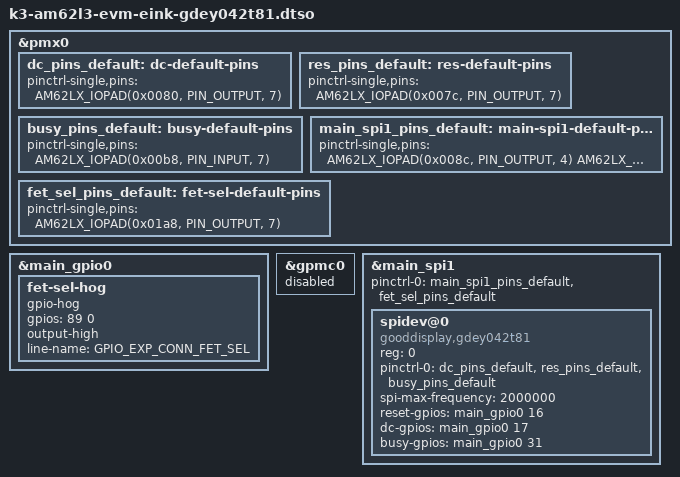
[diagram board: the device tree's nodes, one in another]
// SPDX-License-Identifier: GPL-2.0-or-later OR MIT
/**
 * DT Overlay for GoodDisplay GDEY042T81 E-Ink Display on AM62L3 EVM
 *
 * Pin mapping (matching k3-am62l3-evm-epaper.dtso):
 * P5  --> BUSY
 * P25 --> GND
 * P26 --> RST
 * P27 --> SPI CLK
 * P28 --> DC
 * P29 --> SPI DAT (MOSI)
 * P30 --> SPI CS
 *
 * Copyright (C) 2025 Texas Instruments Incorporated - https://www.ti.com/
 */

/dts-v1/;
/plugin/;

#include <dt-bindings/gpio/gpio.h>
#include "k3-pinctrl.h"

&pmx0 {
	dc_pins_default: dc-default-pins {
		pinctrl-single,pins = <
			AM62LX_IOPAD(0x0080, PIN_OUTPUT, 7) /* (K22) GPMC0_AD2.GPIO0_17 */
		>;
	};

	res_pins_default: res-default-pins {
		pinctrl-single,pins = <
			AM62LX_IOPAD(0x007c, PIN_OUTPUT, 7) /* (L23) GPMC0_AD1.GPIO0_16 */
		>;
	};

	busy_pins_default: busy-default-pins {
		pinctrl-single,pins = <
			AM62LX_IOPAD(0x00b8, PIN_INPUT, 7) /* (L21) GPMC0_AD0.GPIO0_31 */
		>;
	};

	main_spi1_pins_default: main-spi1-default-pins {
		pinctrl-single,pins = <
			AM62LX_IOPAD(0x008c, PIN_OUTPUT, 4) /* (H22) GPMC0_AD5.SPI1_CLK */
			AM62LX_IOPAD(0x0088, PIN_OUTPUT, 4) /* (K23) GPMC0_AD4.SPI1_CS0 */
			AM62LX_IOPAD(0x0084, PIN_OUTPUT, 4) /* (J23) GPMC0_AD3.SPI1_D1 */
		>;
	};

	fet_sel_pins_default: fet-sel-default-pins {
		pinctrl-single,pins = <
			AM62LX_IOPAD(0x01a8, PIN_OUTPUT, 7) /* (E13) SPI0_CLK.GPIO0_89 */
		>;
	};
};

&main_gpio0 {
	fet-sel-hog {
		/* VOUT0 FET switch selection */
		gpio-hog;
		gpios = <89 0>;
		output-high;
		line-name = "GPIO_EXP_CONN_FET_SEL";
	};
};

&gpmc0 {
	status = "disabled";
};

&main_spi1 {
	pinctrl-names = "default";
	pinctrl-0 = <&main_spi1_pins_default>, <&fet_sel_pins_default>;
	status = "okay";
	#address-cells = <1>;
	#size-cells = <0>;

	spidev@0 {
		compatible = "gooddisplay,gdey042t81";
		reg = <0>;
		pinctrl-names = "default";
		pinctrl-0 = <&dc_pins_default>,
			    <&res_pins_default>,
			    <&busy_pins_default>;
		spi-max-frequency = <2000000>;
		reset-gpios = <&main_gpio0 16 GPIO_ACTIVE_HIGH>;
		dc-gpios = <&main_gpio0 17 GPIO_ACTIVE_HIGH>;
		busy-gpios = <&main_gpio0 31 GPIO_ACTIVE_HIGH>;
	};
};
